# M55M1 register map
File version: 1.0
Registers are 32-bit, read-write, reset 0x0 unless marked. A register's access mark holds for its fields unless they carry their own. Offsets are from the block's base; [hi:lo] are bit positions; {n}, {i} and the like mark numbered series; 'fields as' and 'values as' point back to an identical list.

## CRYPTO_NS (part 1 of 2) — CRYPTO Register Map
Base 0x5020A000
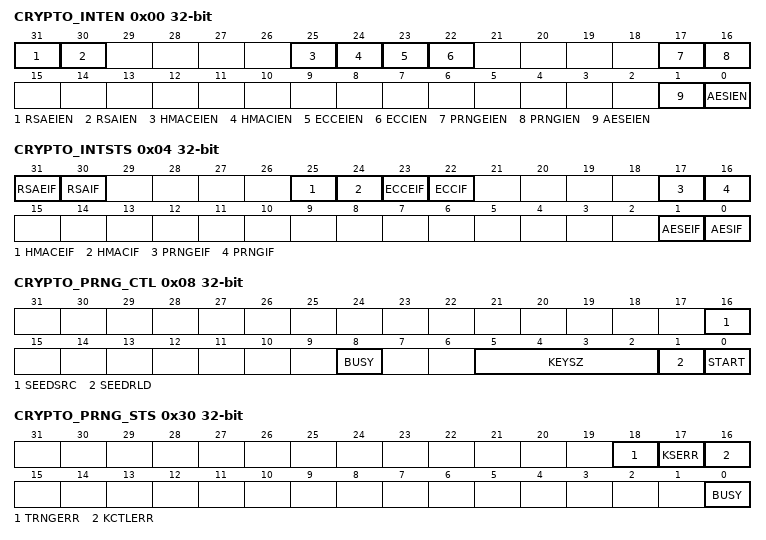
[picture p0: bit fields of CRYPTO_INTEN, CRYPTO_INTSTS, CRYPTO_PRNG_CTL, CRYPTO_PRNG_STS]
0x00 CRYPTO_INTEN — Crypto Interrupt Enable Control Register
  [31] RSAEIEN — RSA Error Interrupt Enable Bit
    0=RSA error interrupt flag Disabled; 1=RSA error interrupt flag Enabled
  [30] RSAIEN — RSA Interrupt Enable Bit
    0=RSA interrupt Disabled; 1=RSA interrupt Enabled
  [25] HMACEIEN — SHA/HMAC Error Interrupt Enable Bit
    0=SHA/HMAC error interrupt flag Disabled; 1=HMAC error interrupt flag Enabled
  [24] HMACIEN — SHA/HMAC Interrupt Enable Bit. Note: In DMA mode, an interrupt will be triggered when an amount of data set in HMAC_DMA_CNT is fed into the SHA/HMAC engine. In Non-DMA mode, an interrupt will be triggered when the SHA/HMAC engine finishes the operation.
    0=SHA/HMAC interrupt Disabled; 1=SHA/HMAC interrupt Enabled
  [23] ECCEIEN — ECC Error Interrupt Enable Bit
    0=ECC error interrupt flag Disabled; 1=ECC error interrupt flag Enabled
  [22] ECCIEN — ECC Interrupt Enable Bit. Note: In DMA mode, an interrupt will be triggered when an amount of data set in ECC_DMA_CNT is fed into the ECC engine. In Non-DMA mode, an interrupt will be triggered when the ECC engine finishes the operation.
    0=ECC interrupt Disabled; 1=ECC interrupt Enabled
  [17] PRNGEIEN — PRNG Error Flag Enable Bit
    0=PRNG error interrupt flag Disabled; 1=PRNG error interrupt flag Enabled
  [16] PRNGIEN — PRNG Interrupt Enable Bit
    0=PRNG interrupt Disabled; 1=PRNG interrupt Enabled
  [1] AESEIEN — AES Error Flag Enable Bit
    0=AES error interrupt flag Disabled; 1=AES error interrupt flag Enabled
  [0] AESIEN — AES Interrupt Enable Bit. Note: In DMA mode, an interrupt will be triggered when an amount of data set in AES_DMA_CNT is fed into the AES engine. In Non-DMA mode, an interrupt will be triggered when the AES engine finishes the operation.
    0=AES interrupt Disabled; 1=AES interrupt Enabled
0x04 CRYPTO_INTSTS — Crypto Interrupt Flag
  [31] RSAEIF — RSA Error Interrupt Flag. This register includes operating and setting error. The detail flag is shown in CRYPTO_RSA_STS register. Note: This bit is cleared by writing 1, and it has no effect by writing 0.
    0=No RSA error; 1=RSA error interrupt
  [30] RSAIF — RSA Finish Interrupt Flag. Note: This bit is cleared by writing 1, and it has no effect by writing 0.
    0=No RSA interrupt; 1=RSA operation done interrupt
  [25] HMACEIF — SHA/HMAC Error Flag. This register includes operating and setting error. The detail flag is shown in CRYPTO_HMAC_STS register. Note: This bit is cleared by writing 1, and it has no effect by writing 0.
    0=No SHA/HMAC error; 1=SHA/HMAC error interrupt
  [24] HMACIF — SHA/HMAC Finish Interrupt Flag. Note: This bit is cleared by writing 1, and it has no effect by writing 0.
    0=No SHA/HMAC interrupt; 1=SHA/HMAC operation done interrupt
  [23] ECCEIF — ECC Error Flag. This register includes operating and setting error. The detail flag is shown in CRYPTO_ECC_STS register. Note: This bit is cleared by writing 1, and it has no effect by writing 0.
    0=No ECC error; 1=ECC error interrupt
  [22] ECCIF — ECC Finish Interrupt Flag. Note: This bit is cleared by writing 1, and it has no effect by writing 0.
    0=No ECC interrupt; 1=ECC operation done interrupt
  [17] PRNGEIF — PRNG Error Flag. This register includes operating and setting error. The detail flag is shown in CRYPTO_PRNG_STS register. Note: This bit is cleared by writing 1, and it has no effect by writing 0.
    0=No PRNG error; 1=PRNG error interrupt
  [16] PRNGIF — PRNG Finish Interrupt Flag. Note: This bit is cleared by writing 1, and it has no effect by writing 0.
    0=No PRNG interrupt; 1=PRNG done interrupt
  [1] AESEIF — AES Error Flag. This register includes operating and setting error. The detail flag is shown in CRYPTO_AES_STS register. Note: This bit is cleared by writing 1, and it has no effect by writing 0.
    0=No AES error; 1=AES error interrupt
  [0] AESIF — AES Finish Interrupt Flag. Note: This bit is cleared by writing 1, and it has no effect by writing 0.
    0=No AES interrupt; 1=AES done interrupt
0x08 CRYPTO_PRNG_CTL — PRNG Control Register
  [16] SEEDSRC — Seed Source. Note: When SEEDRLD is set to 0, this bit (SEEDSRC) is meaningless.
    0=Seed is from TRNG; 1=Seed is from PRNG seed register
  [8] BUSY ro — PRNG Busy (Read Only)
    0=PRNG engine is idle; 1=PRNG engine is generating CRYPTO_PRNG_KEYx
  [5:2] KEYSZ — PRNG Generate Key Size. Note: 283~571 bits are only generated for Key Store.
    0=128 bits; 1=163 bits; 2=192 bits; 3=224 bits; 4=233 bits; 5=255 bits; 6=256 bits; 7=283 bits (only for Key Store); 8=384 bits (only for Key Store); 9=409 bits (only for Key Store); 10=512 bits (only for Key Store); 11=521 bits (only for Key Store); 12=571 bits (only for Key Store)
  [1] SEEDRLD — Reload New Seed for PRNG Engine
    0=Generating key based on the current seed; 1=Reload new seed
  [0] START — Start PRNG Engine
    0=Stop PRNG engine; 1=Generate new key and store the new key to register CRYPTO_PRNG_KEYx, which will be cleared when the new key is generated
0x0C CRYPTO_PRNG_SEED wo reset not defined — Seed for PRNG
  [31:0] SEED — Seed for PRNG (Write Only). The bits store the seed for PRNG engine. Note: In TRNG+PRNG mode, the seed is from TRNG engine, and it will not be stored in this register.
{0x10+4i} CRYPTO_PRNG_KEY{i} ro reset not defined (i=0..7) — PRNG Generated Key{i}
  [31:0] KEY — Store PRNG Generated Key (Read Only). The bits store the key that is generated by PRNG.
0x30 CRYPTO_PRNG_STS ro — PRNG Status Register
  [18] TRNGERR — True Random Number Generator Error Flag
    0=No error; 1=Getting random number or seed failed
  [17] KSERR — PRNG Access Key Store Error Flag
    0=No error; 1=Access Key Store failed
  [16] KCTLERR — PRNG Key Control Register Error Flag
    0=No error; 1=PRNG key control error. When PRNG execute ECDSA or ECDH, but PRNG seed not from TRNG or key is not written to the SRAM of Key Store (WSDST, CRYPTO_PRNG_KSCTL[23:22] is not equal to '00')
  [0] BUSY — PRNG Busy Flag
    values as CRYPTO_PRNG_CTL.BUSY
{0x50+4i} CRYPTO_AES_FDBCK{i} ro (i=0..3) — AES Engine Output Feedback Data After Cryptographic Operation
  [31:0] FDBCK — AES Feedback Information. The feedback value is 128 bits in size. The AES engine uses the data from CRYPTO_AES_FDBCKx as the data inputted to CRYPTO_AES_IVx for the next block in DMA cascade mode. The AES engine outputs feedback information for IV in the next block's operation. Software can use this feedback information to implement more than four DMA channels. Software can store that feedback value temporarily. After switching back, fill the stored feedback value to CRYPTO_AES_IVx in the same channel operation, and then continue the operation with the original setting.
0x80 CRYPTO_AES_GCM_IVCNT0 — AES GCM IV Byte Count Register 0
  [31:0] CNT — AES GCM IV Byte Count. The bit length of IV is 64 bits for AES GCM mode. The CRYPTO_AES_GCM_IVCNT0 keeps the low weight byte count of initial vector (i.e., len(IV)[34:3]) of AES GCM mode and can be read and written.
0x84 CRYPTO_AES_GCM_IVCNT1 — AES GCM IV Byte Count Register 1
  [28:0] CNT — AES GCM IV Byte Count. The bit length of IV is 64 bits for AES GCM mode. The CRYPTO_AES_GCM_IVCNT1 keeps the high weight byte count of initial vector (i.e., len(IV)[64:35]) of AES GCM mode and can be read and written.
0x88 CRYPTO_AES_GCM_ACNT0 — AES GCM A Byte Count Register 0
  [31:0] CNT — AES GCM A Byte Count. The bit length of A is 64 bits for AES GCM mode. The CRYPTO_AES_GCM_ACNT0 keeps the low weight byte count of the additional authenticated data (i.e., len(A)[34:3]) of AES GCM mode and can be read and written.
0x8C CRYPTO_AES_GCM_ACNT1 — AES GCM A Byte Count Register 1
  [28:0] CNT — AES GCM A Byte Count. The bit length of A is 64 bits for AES GCM mode. The CRYPTO_AES_GCM_ACNT0 keeps the high weight byte count of the additional authenticated data (i.e., len(A)[63:35]) of AES GCM mode and can be read and written.
0x90 CRYPTO_AES_GCM_PCNT0 — AES GCM P Byte Count Register 0
  [31:0] CNT — AES GCM P Byte Count. The bit length of Por C is 39 bits for AES GCM mode. The CRYPTO_AES_GCM_PCNT0 keeps the low weight byte count of the plaintext or ciphertext (i.e., len(P)[34:3] or len(C)[34:3]) of AES GCM mode and can be read and written.
0x94 CRYPTO_AES_GCM_PCNT1 — AES GCM P Byte Count Register 1
  [28:0] CNT — AES GCM P Byte Count. The bit length of Por C is 39 bits for AES GCM mode. The CRYPTO_AES_GCM_PCNT1 keeps the high weight byte count of the plaintext or ciphertext (i.e., len(P)[38:35] or len(C)[38:35]) of AES GCM mode and can be read and written. The bit length of Por C is 64 bits for AES CCM mode. The CRYPTO_AES_GCM_PCNT1 keeps the high weight byte count of the plaintext or ciphertext (i.e., len(P)[63:35] or len(C)[63:35]) of AES CCM mode and can be read and written.
0xA0 CRYPTO_AES_FBADDR — AES DMA Feedback Address Register
  [31:0] FBADDR — AES DMA Feedback Address. In DMA cascade mode, software can update DMA feedback address register for automatically reading and writing feedback values via DMA. The FBADDR keeps the feedback address of the feedback data for the next cascade operation. Based on the feedback address, the AES accelerator can read the feedback data of the last cascade operation from SRAM memory space and write the feedback data of the current cascade operation to SRAM memory space. The start of feedback address should be located at word boundary. In other words, bit 1 and 0 of FBADDR are ignored. FBADDR can be read and written. In DMA mode, software can update the next CRYPTO_AES_FBADDR before triggering START.
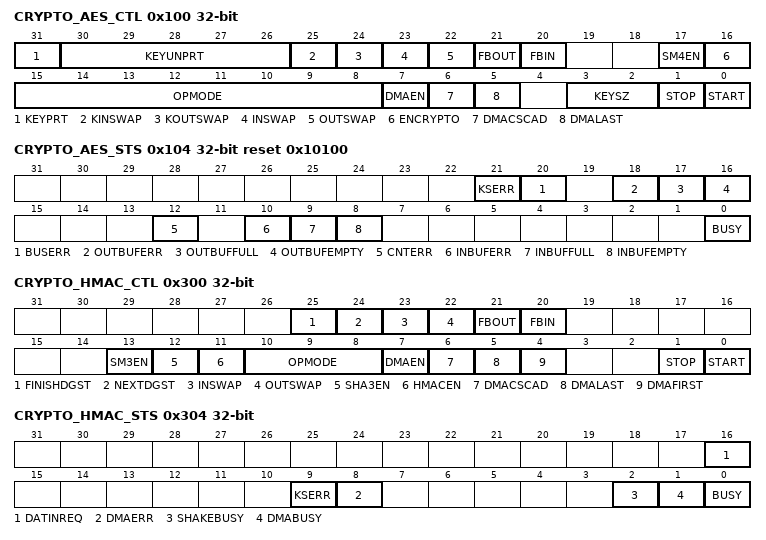
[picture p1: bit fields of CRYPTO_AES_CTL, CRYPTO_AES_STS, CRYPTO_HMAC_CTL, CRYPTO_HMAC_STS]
0x100 CRYPTO_AES_CTL — AES Control Register
  [31] KEYPRT — Protect Key. Read as a flag to reflect KEYPRT.
    0=No effect; 1=Protect the content of the AES key from reading. The return value for reading CRYPTO_AES_KEYx is not the content of the registers CRYPTO_AES_KEYx. Once it is set, it can be cleared by asserting KEYUNPRT. The key content would be cleared as well
  [30:26] KEYUNPRT — Unprotect Key. Writing 0 to CRYPTO_AES_CTL[31] and '10110' to CRYPTO_AES_CTL[30:26] is to unprotect the AES key. The KEYUNPRT can be read and written. When it is written as the AES engine is operating, BUSY flag is 1, there would be no effect on KEYUNPRT.
  [25] KINSWAP — AES Engine Input Key and Initial Vector Swap
    0=Keep the original order; 1=The order that CPU feeds key and initial vector to the accelerator will be changed from {byte3, byte2, byte1, byte0} to {byte0, byte1, byte2, byte3}
  [24] KOUTSWAP — AES Engine Output Key, Initial Vector and Feedback Swap
    0=Keep the original order; 1=The order that CPU reads key, initial vector and feedback from the accelerator will be changed from {byte3, byte2, byte1, byte0} to {byte0, byte1, byte2, byte3}
  [23] INSWAP — AES Engine Input Data Swap
    0=Keep the original order; 1=The order that CPU feeds data to the accelerator will be changed from {byte3, byte2, byte1, byte0} to {byte0, byte1, byte2, byte3}
  [22] OUTSWAP — AES Engine Output Data Swap
    0=Keep the original order; 1=The order that CPU reads data from the accelerator will be changed from {byte3, byte2, byte1, byte0} to {byte0, byte1, byte2, byte3}
  [21] FBOUT — Feedback Output From AES Via DMA Automatically
    0=DMA automatic feedback output function Disabled; 1=DMA automatic feedback output function Enabled when DMAEN = 1
  [20] FBIN — Feedback Input to AES Via DMA Automatically
    0=DMA automatic feedback input function Disabled; 1=DMA automatic feedback input function Enabled when DMAEN = 1
  [17] SM4EN — SM4 Engine Enable
    0=AES engine Enabled; 1=SM4 engine Enabled
  [16] ENCRYPTO — AES Encryption/Decryption
    0=AES engine executes decryption operation; 1=AES engine executes encryption operation
  [15:8] OPMODE — AES Engine Operation Modes
    0=ECB (Electronic Codebook Mode) 0x01 = CBC (Cipher Block Chaining Mode); 2=CFB (Cipher Feedback Mode); 3=OFB (Output Feedback Mode); 4=CTR (Counter Mode); 16=CBC-CS1 (CBC Ciphertext-Stealing 1 Mode); 17=CBC-CS2 (CBC Ciphertext-Stealing 2 Mode); 18=CBC-CS3 (CBC Ciphertext-Stealing 3 Mode); 32=GCM (Galois/Counter Mode); 33=GHASH (Galois Hash Function); 34=CCM (Counter with CBC-MAC Mode)
  [7] DMAEN — AES Engine DMA Enable Bit. The AES engine operates in DMA mode, and data movement from/to the engine is done by DMA logic.
    0=AES DMA engine Disabled; 1=AES_DMA engine Enabled
  [6] DMACSCAD — AES Engine DMA with Cascade Mode. Note: The last two blocks of AES-CBC-CS1/2/3 must be in the last cascade operation.
    0=DMA cascade function Disabled; 1=In DMA cascade mode, software can update DMA source address register, destination address register, and byte count register during a cascade operation, without finishing the accelerator operation
  [5] DMALAST — AES Last Block. In DMA mode, this bit must be set as beginning the last DMA cascade round. In Non-DMA mode, this bit must be set when feeding in the last block of data in ECB, CBC, CTR, OFB, and CFB mode, and feeding in the (last-1) block of data at CBC-CS1, CBC-CS2, and CBC-CS3 mode. This bit is always 0 when it is read back, and must be written again once START is triggered.
  [3:2] KEYSZ — AES Key Size. This bit defines three different key size for AES operation.
  [1] STOP — AES Engine Stop. Note: This bit is always 0 when it is read back.
    0=No effect; 1=Stop AES engine
  [0] START — AES Engine Start. Note: This bit is always 0 when it is read back.
    0=No effect; 1=Start AES engine. BUSY flag will be set
0x104 CRYPTO_AES_STS ro reset 0x10100 — AES Engine Flag
  [21] KSERR — AES Engine Access Key Store Error Flag
    0=No error; 1=Key Store access error will stop AES engine
  [20] BUSERR — AES DMA Access Bus Error Flag
    0=No error; 1=Bus error will stop DMA operation and AES engine
  [18] OUTBUFERR — AES Out Buffer Error Flag
    0=No error; 1=Error happened during getting the result from AES engine
  [17] OUTBUFFULL — AES Out Buffer Full Flag
    0=AES output buffer is not full; 1=AES output buffer is full, and software needs to get data from CRYPTO_AES_DATOUT. Otherwise, the AES engine will be pending since the output buffer is full
  [16] OUTBUFEMPTY — AES Out Buffer Empty
    0=AES output buffer is not empty. There are some valid data kept in output buffer; 1=AES output buffer is empty. Software cannot get data from CRYPTO_AES_DATOUT. Otherwise, the flag OUTBUFERR will be set to 1 since the output buffer is empty
  [12] CNTERR — CRYPTO_AES_CNT Setting Error
    0=No error in CRYPTO_AES_CNT setting; 1=CRYPTO_AES_CNT is 0 if DMAEN (CRYPTO_AES_CTL[7]) is enabled
  [10] INBUFERR — AES Input Buffer Error Flag
    0=No error; 1=Error happened during feeding data to the AES engine
  [9] INBUFFULL — AES Input Buffer Full Flag
    0=AES input buffer is not full. Software can feed the data into the AES engine; 1=AES input buffer is full. Software cannot feed data to the AES engine. Otherwise, the flag INBUFERR will be set to 1
  [8] INBUFEMPTY — AES Input Buffer Empty
    0=There are some data in input buffer waiting for the AES engine to process; 1=AES input buffer is empty. Software needs to feed data to the AES engine. Otherwise, the AES engine will be pending to wait for input data
  [0] BUSY — AES Engine Busy
    0=The AES engine is idle or finished; 1=The AES engine is under processing
0x108 CRYPTO_AES_DATIN — AES Engine Data Input Port Register
  [31:0] DATIN — AES Engine Input Port. CPU feeds data to AES engine through this port by checking CRYPTO_AES_STS. Feed data as INBUFFULL is 0.
0x10C CRYPTO_AES_DATOUT ro — AES Engine Data Output Port Register
  [31:0] DATOUT — AES Engine Output Port. CPU gets results from the AES engine through this port by checking CRYPTO_AES_STS. Get data as OUTBUFEMPTY is 0.
{0x110+4i} CRYPTO_AES_KEY{i} (i=0..7) — AES Key Word {i} Register
  [31:0] KEY — CRYPTO_AES_KEYx. The KEY keeps the security key for AES operation. The security key for AES accelerator can be 128, 192, or 256 bits and four, six, or eight 32-bit registers are to store each security key. {CRYPTO_AES_KEY3, CRYPTO_AES_KEY2, CRYPTO_AES_KEY1, CRYPTO_AES_KEY0} stores the 128-bit security key for AES operation. {CRYPTO_AES_KEY5, CRYPTO_AES_KEY4, CRYPTO_AES_KEY3, CRYPTO_AES_KEY2, CRYPTO_AES_KEY1, CRYPTO_AES_KEY0} stores the 192-bit security key for AES operation. {CRYPTO_AES_KEY7, CRYPTO_AES_KEY6, CRYPTO_AES_KEY5, CRYPTO_AES_KEY4, CRYPTO_AES_KEY3, CRYPTO_AES_KEY2, CRYPTO_AES_KEY1, CRYPTO_AES_KEY0} stores the 256-bit security key for AES operation.
{0x130+4i} CRYPTO_AES_IV{i} (i=0..3) — AES Initial Vector Word {i} Register
  [31:0] IV — AES Initial Vectors. Four initial vectors (CRYPTO_AES_IV0, CRYPTO_AES_IV1, CRYPTO_AES_IV2, and CRYPTO_AES_IV3) are for AES operating in CBC, CFB, and OFB mode. Four registers (CRYPTO_AES_IV0, CRYPTO_AES_IV1, CRYPTO_AES_IV2, and CRYPTO_AES_IV3) act as Nonce counter when the AES engine is operating in CTR mode.
0x140 CRYPTO_AES_SADDR — AES DMA Source Address Register
  [31:0] SADDR — AES DMA Source Address. The AES accelerator supports DMA function to transfer the plain text between SRAM memory space and embedded FIFO. The SADDR keeps the source address of the data buffer where the source text is stored. Based on the source address, the AES accelerator can read the plain text (encryption) / cipher text (decryption) from SRAM memory space and do AES operation. The start of source address should be located at word boundary. In other words, bit 1 and 0 of SADDR are ignored. SADDR can be read and written. Writing to SADDR while the AES accelerator is operating doesn't affect the current AES operation. But the value of SADDR will be updated later on. Consequently, software can prepare the DMA source address for the next AES operation. In DMA mode, software can update the next CRYPTO_AES_SADDR before triggering START. The value of CRYPTO_AES_SADDR and CRYPTO_AES_DADDR can be the same.
0x144 CRYPTO_AES_DADDR — AES DMA Destination Address Register
  [31:0] DADDR — AES DMA Destination Address. The AES accelerator supports DMA function to transfer the cipher text between SRAM memory space and embedded FIFO. The DADDR keeps the destination address of the data buffer where the engine output's text will be stored. Based on the destination address, the AES accelerator can write the cipher text (encryption) / plain text (decryption) back to SRAM memory space after the AES operation is finished. The start of destination address should be located at word boundary. In other words, bit 1 and 0 of DADDR are ignored. DADDR can be read and written. Writing to DADDR while the AES accelerator is operating doesn't affect the current AES operation. But the value of DADDR will be updated later on. Consequently, software can prepare the destination address for the next AES operation. In DMA mode, software can update the next CRYPTO_AES_DADDR before triggering START. The value of CRYPTO_AES_SADDR and CRYPTO_AES_DADDR can be the same.
0x148 CRYPTO_AES_CNT — AES Byte Count Register
  [31:0] CNT — AES Byte Count. The CRYPTO_AES_CNT keeps the byte count of source text that is for the AES engine operating in DMA mode. The CRYPTO_AES_CNT is 32-bit and the maximum of byte count is 4G bytes. CRYPTO_AES_CNT can be read and written. Writing to CRYPTO_AES_CNT while the AES accelerator is operating doesn't affect the current AES operation. But the value of CRYPTO_AES_CNT will be updated later on. Consequently, software can prepare the byte count of data for the next AES operation. According to CBC-CS1, CBC-CS2, and CBC-CS3 standard, the count of operation data must be more than 16 bytes. Operations that are qual to or less than one block will output unexpected result. In Non-DMA ECB, CBC, CFB, OFB, CTR, CCM and GCM mode, CRYPTO_AES_CNT must be set as byte count for the last block of data before feeding in the last block of data. In Non-DMA CBC-CS1, CBC-CS2, and CBC-CS3 mode, CRYPTO_AES_CNT must be set as byte count for the last two blocks of data before feeding in the last two blocks of data. In AES GCM mode without DMA cascade function, the value of CRYPTO_AES_CNT is equal to the total value of {CRYPTO_AES_GCM_IVCNT1, CRYPTO_AES_GCM_IVCNT0}, {CRYPTO_AES_GCM_ACNT1, CRYPTO_AES_GCM_ACNT0} and {CRYPTO_AES_GCM_PCNT1, CRYPTO_AES_GCM_PCNT0}. In AES GCM mode with DMA cascade function, the value of CRYPTO_AES_CNT represents the byte count of source text in this cascade function. Thus, the value of CRYPTO_AES_CNT is less than or equal to the total value of {CRYPTO_AES_GCM_IVCNT1, CRYPTO_AES_GCM_IVCNT0}, {CRYPTO_AES_GCM_ACNT1, CRYPTO_AES_GCM_ACNT0} and {CRYPTO_AES_GCM_PCNT1, CRYPTO_AES_GCM_PCNT0} and must be block alignment. In AES CCM mode without DMA cascade function, the value of CRYPTO_AES_CNT is equal to the total value of {CRYPTO_AES_GCM_ACNT1, CRYPTO_AES_GCM_ACNT0} and {CRYPTO_AES_GCM_PCNT1, CRYPTO_AES_GCM_PCNT0}. In AES CCM mode with DMA cascade function, the value of CRYPTO_AES_CNT represents the byte count of source text in this cascade function. Thus, the value of CRYPTO_AES_CNT is less than or equal to the total value of {CRYPTO_AES_GCM_ACNT1, CRYPTO_AES_GCM_ACNT0} and {CRYPTO_AES_GCM_PCNT1, CRYPTO_AES_GCM_PCNT0} and must be block alignment, except for the last block of plaintext or ciphertext.
0x300 CRYPTO_HMAC_CTL — SHA/HMAC Control Register
  [25] FINISHDGST — SHAKE128/256 Next Digest Finish
    0=No effect; 1=finish generating the next digest
  [24] NEXTDGST — SHAKE128/256 Next Digest Start
    0=No effect; 1=Start SHAKE engine to generate the next digest only when SHAKEBUSY is 0. BUSY and SHAKEBUSY flag will be set
  [23] INSWAP — SHA/HMAC Engine Input Data Swap
    values as CRYPTO_AES_CTL.INSWAP
  [22] OUTSWAP — SHA/HMAC Engine Output Data Swap
    values as CRYPTO_AES_CTL.INSWAP
  [21] FBOUT — Feedback Output From SHA/HMAC Via DMA Automatically
    values as CRYPTO_AES_CTL.FBOUT
  [20] FBIN — Feedback Input to SHA/HMAC Via DMA Automatically
    values as CRYPTO_AES_CTL.FBIN
  [13] SM3EN — SM3 Engine Enable Bit
    0=Execute other function; 1=Execute SM3 function if SHA3EN=0
  [12] SHA3EN — SHA3 Engine Enable Bit
    0=Execute other function; 1=Execute SHA3 function if SM3EN=0
  [11] HMACEN — HMAC_SHA Engine Operating Mode
    0=Execute SHA function; 1=Execute HMAC function
  [10:8] OPMODE — SHA/HMAC Engine Operation Modes
  [7] DMAEN — SHA/HMAC Engine DMA Enable Bit. SHA/HMAC engine operates in DMA mode, and data movement from/to the engine is done by DMA logic.
    0=SHA/HMAC DMA engine Disabled; 1=SHA/HMAC DMA engine Enabled
  [6] DMACSCAD — SHA/HMAC Engine DMA with Cascade Mode
    values as CRYPTO_AES_CTL.DMACSCAD
  [5] DMALAST — SHA/HMAC Last Block. This bit must be set as feeding in last byte of data.
  [4] DMAFIRST — SHA/HMAC First Block in Cascade function. This bit must be set as feeding in first byte of data.
  [1] STOP — SHA/HMAC Engine Stop. Note: This bit is always 0 when it is read back.
    0=No effect; 1=Stop SHA/HMAC engine
  [0] START — SHA/HMAC Engine Start. Note: This bit is always 0 when it is read back.
    0=No effect; 1=Start SHA/HMAC engine. BUSY flag will be set
0x304 CRYPTO_HMAC_STS ro — SHA/HMAC Status Flag
  [16] DATINREQ — SHA/HMAC Non-DMA Mode Data Input Request
    0=No effect; 1=Request SHA/HMAC Non-DMA mode data input
  [9] KSERR — HMAC Engine Access Key Store Error Flag
    0=No error; 1=Access error will stop HMAC engine
  [8] DMAERR — SHA/HMAC Engine DMA Error Flag
    0=Show the SHA/HMAC engine access normal; 1=Show the SHA/HMAC engine access error
  [2] SHAKEBUSY — SHAKE Engine Busy Flag
    0=SHAKE engine is idle or finished; 1=SHAKE engine is busy
  [1] DMABUSY — SHA/HMAC Engine DMA Busy Flag
    0=SHA/HMAC DMA engine is idle or finished; 1=SHA/HMAC DMA engine is busy
  [0] BUSY — SHA/HMAC Engine Busy
    0=SHA/HMAC engine is idle or finished; 1=SHA/HMAC engine is busy
{0x308+4i} CRYPTO_HMAC_DGST{i} ro (i=0..15) — SHA/HMAC Output Feedback Data {i}
  [31:0] DGST — SHA/HMAC Output Feedback Data Output Register. For SHA-160, the digest is stored in CRYPTO_HMAC_DGST0 ~ CRYPTO_HMAC_DGST4. For SHA-224, the digest is stored in CRYPTO_HMAC_DGST0 ~ CRYPTO_HMAC_DGST6. For SHA-256, the digest is stored in CRYPTO_HMAC_DGST0 ~ CRYPTO_HMAC_DGST7. For SHA-384, the digest is stored in CRYPTO_HMAC_DGST0 ~ CRYPTO_HMAC_DGST11. For SHA-512, the digest is stored in CRYPTO_HMAC_DGST0 ~ CRYPTO_HMAC_DGST15.
0x348 CRYPTO_HMAC_KEYCNT — SHA/HMAC Key Byte Count Register
  [31:0] KEYCNT — SHA/HMAC Key Byte Count. The CRYPTO_HMAC_KEYCNT keeps the byte count of key that SHA/HMAC engine operates. The register is 32-bit and the maximum byte count is 4G bytes. It can be read and written. Writing to the register CRYPTO_HMAC_KEYCNT as the SHA/HMAC accelerator operating doesn't affect the current SHA/HMAC operation. But the value of CRYPTO_HMAC_KEYCNT will be updated later on. Consequently, software can prepare the key count for the next SHA/HMAC operation. Note: CRYPTO_HMAC_KEYCNT must be zero when HMAC key from Key Store.
0x34C CRYPTO_HMAC_SADDR — SHA/HMAC DMA Source Address Register
  [31:0] SADDR — SHA/HMAC DMA Source Address. The SHA/HMAC accelerator supports DMA function to transfer the plain text between SRAM memory space and embedded FIFO. The CRYPTO_HMAC_SADDR keeps the source address of the data buffer where the source text is stored. Based on the source address, the SHA/HMAC accelerator can read the plain text from SRAM memory space and do SHA/HMAC operation. The start of source address should be located at word boundary. In other words, bit 1 and 0 of CRYPTO_HMAC_SADDR are ignored. CRYPTO_HMAC_SADDR can be read and written. Writing to CRYPTO_HMAC_SADDR while the SHA/HMAC accelerator is operating doesn't affect the current SHA/HMAC operation. But the value of CRYPTO_HMAC_SADDR will be updated later on. Consequently, software can prepare the DMA source address for the next SHA/HMAC operation. In DMA mode, software can update the next CRYPTO_HMAC_SADDR before triggering START. CRYPTO_HMAC_SADDR and CRYPTO_HMAC_DADDR can be the same in the value.
0x350 CRYPTO_HMAC_DMACNT — SHA/HMAC Byte Count Register
  [31:0] DMACNT — SHA/HMAC Operation Byte Count. The CRYPTO_HMAC_DMACNT keeps the byte count of source text that is for the SHA/HMAC engine operating in DMA mode. The CRYPTO_HMAC_DMACNT is 32-bit and the maximum of byte count is 4G bytes. CRYPTO_HMAC_DMACNT can be read and written. Writing to CRYPTO_HMAC_DMACNT while the SHA/HMAC accelerator is operating doesn't affect the current SHA/HMAC operation. But the value of CRYPTO_HMAC_DMACNT will be updated later on. Consequently, software can prepare the byte count of data for the next SHA/HMAC operation. In Non-DMA mode, CRYPTO_HMAC_DMACNT must be set as the byte count of the last block before feeding in the last block of data.
0x354 CRYPTO_HMAC_DATIN — SHA/HMAC Engine Non-DMA Mode Data Input Port Register
  [31:0] DATIN — SHA/HMAC Engine Input Port. CPU feeds data to SHA/HMAC engine through this port by checking CRYPTO_HMAC_STS. Feed data as DATINREQ is 1.
